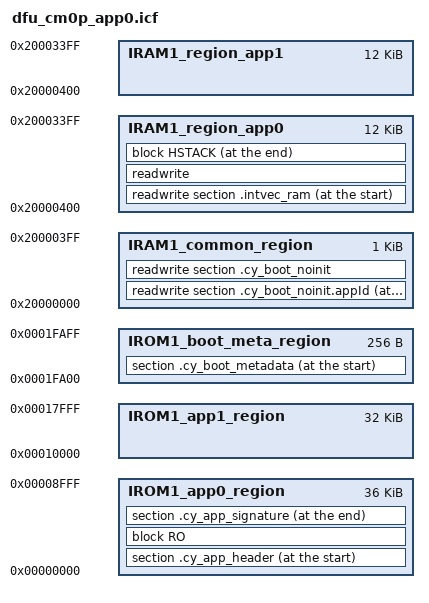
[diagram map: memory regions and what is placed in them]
/*******************************************************************************
* \file dfu_cm0p_app0.icf
* \version 4.10
*
* Linker file for the IAR compiler.
* Used for the DFU SDK application 0 firmware project.
*
* The main purpose of the linker script is to describe how the sections in the
* input files should be mapped into the output file, and to control the memory
* layout of the output file.
*
* \note The entry point is fixed and starts at 0x00000000. The valid application
* image should be placed there.
*
* \note The linker files included with the PDL template projects must be generic
* and handle all common use cases. Your project may not use every section
* defined in the linker files. In that case you may see warnings during the
* build process. In your project, you can simply comment out or remove the
* relevant code in the linker file.
*
********************************************************************************
* \copyright
* Copyright 2019-2020 Cypress Semiconductor Corporation
* SPDX-License-Identifier: Apache-2.0
*
* Licensed under the Apache License, Version 2.0 (the "License");
* you may not use this file except in compliance with the License.
* You may obtain a copy of the License at
*
*     http://www.apache.org/licenses/LICENSE-2.0
*
* Unless required by applicable law or agreed to in writing, software
* distributed under the License is distributed on an "AS IS" BASIS,
* WITHOUT WARRANTIES OR CONDITIONS OF ANY KIND, either express or implied.
* See the License for the specific language governing permissions and
* limitations under the License.
*******************************************************************************/

/*###ICF### Section handled by ICF editor, don't touch! ****/
/*-Editor annotation file-*/
/* IcfEditorFile="$TOOLKIT_DIR$\config\ide\IcfEditor\cortex_v1_4.xml" */
/*-Specials-*/
define symbol __ICFEDIT_intvec_start__ = 0x00000000;

/* The symbols below define the location and size of blocks of memory in the target.
 * Use these symbols to specify the memory regions available for allocation.
 */

/* The following symbols control RAM and flash memory allocation.
 * You can change the memory allocation by editing RAM and Flash symbols.
 */
/* RAM */
define symbol __ICFEDIT_region_IRAM1_comon_start__ = 0x20000000;
define symbol __ICFEDIT_region_IRAM1_comon_end__   = 0x200003FF;

define symbol __ICFEDIT_region_IRAM1_app0_start__ = 0x20000400;
define symbol __ICFEDIT_region_IRAM1_app0_end__   = 0x200033FF;

define symbol __ICFEDIT_region_IRAM1_app1_start__ = 0x20000400;
define symbol __ICFEDIT_region_IRAM1_app1_end__   = 0x200033FF;

/* Flash */
define symbol __ICFEDIT_region_IROM1_app0_start__ = 0x00000000;
define symbol __ICFEDIT_region_IROM1_app0_end__   = 0x00008FFF;

define symbol __ICFEDIT_region_IROM1_app1_start__ = 0x00010000;
define symbol __ICFEDIT_region_IROM1_app1_end__   = 0x00017FFF;

/* The region for DFU SDK metadata when it is outside of any application */
define symbol __ICFEDIT_region_IROM1_boot_meta_start__ = 0x0001FA00;
define symbol __ICFEDIT_region_IROM1_boot_meta_end__   = 0x0001FAFF;

/*-Sizes-*/
if (!isdefinedsymbol(__STACK_SIZE)) {
  define symbol __ICFEDIT_size_cstack__ = 0x0400;
} else {
  define symbol __ICFEDIT_size_cstack__ = __STACK_SIZE;
}
define symbol __ICFEDIT_size_proc_stack__ = 0x0;

/* Defines the minimum heap size. The actual heap size will be expanded to the end of the stack region */
if (!isdefinedsymbol(__HEAP_SIZE)) {
    define symbol __ICFEDIT_size_heap__ = 0x0080;
} else {
  define symbol __ICFEDIT_size_heap__ = __HEAP_SIZE;
}
/**** End of ICF editor section. ###ICF###*/


define memory mem with size = 4G;
define region IROM1_app0_region = mem:[from __ICFEDIT_region_IROM1_app0_start__ to __ICFEDIT_region_IROM1_app0_end__];
define region IROM1_app1_region = mem:[from __ICFEDIT_region_IROM1_app1_start__ to __ICFEDIT_region_IROM1_app1_end__];
define region IROM1_boot_meta_region  = mem:[from __ICFEDIT_region_IROM1_boot_meta_start__ to __ICFEDIT_region_IROM1_boot_meta_end__];
define region IRAM1_common_region = mem:[from __ICFEDIT_region_IRAM1_comon_start__ to __ICFEDIT_region_IRAM1_comon_end__];
define region IRAM1_region_app0   = mem:[from __ICFEDIT_region_IRAM1_app0_start__  to __ICFEDIT_region_IRAM1_app0_end__];
define region IRAM1_region_app1   = mem:[from __ICFEDIT_region_IRAM1_app1_start__  to __ICFEDIT_region_IRAM1_app1_end__];


define block CSTACK     with alignment = 8, size = __ICFEDIT_size_cstack__     { };
define block PROC_STACK with alignment = 8, size = __ICFEDIT_size_proc_stack__ { };
define block HEAP       with expanding size, alignment = 8, minimum size = __ICFEDIT_size_heap__ { };
define block HSTACK {block HEAP, block PROC_STACK, last block CSTACK};
define block RO     {first section .intvec, readonly};

/*-Initializations-*/
initialize by copy { readwrite };
do not initialize  { section .noinit, section .intvec_ram,
                     section .cy_boot_noinit.appId, section .cy_boot_noinit };

/*-Placement-*/

/* Flash */
".cy_app_header" : place at start of IROM1_app0_region  { section .cy_app_header };
place in          IROM1_app0_region  { block RO };

".cy_app_signature": place at end of IROM1_app0_region { section .cy_app_signature };

/* RAM */
place at start of IRAM1_common_region   { readwrite section .cy_boot_noinit.appId };
place in          IRAM1_common_region   { readwrite section .cy_boot_noinit };
place at start of IRAM1_region_app0  { readwrite section .intvec_ram};
place in          IRAM1_region_app0  { readwrite };
place at end   of IRAM1_region_app0  { block HSTACK };

/* These sections are used for additional metadata (silicon revision, Silicon/JTAG ID, etc.) storage. */
".cyflashprotect" : place at address mem : 0x90400000 { readonly section .cyflashprotect };
".cymeta"         : place at address mem : 0x90500000 { readonly section .cymeta };
".cychipprotect"  : place at address mem : 0x90600000 { readonly section .cychipprotect };

/* App0 uses it to initialize DFU SDK metadata, in the dfu_user.c file */
".cy_boot_metadata" : place at start of IROM1_boot_meta_region { section .cy_boot_metadata };

keep {  section .cy_app_header,
        section .cy_app_signature,
        section .cyflashprotect,
        section .cymeta,
        section .cychipprotect,
        section .cy_boot_metadata,
        section .cy_boot_noinit,
        section .cy_boot_noinit.appId,
         };


/* The following symbols used by the cymcuelftool. */
/* Flash */
define exported symbol __cy_memory_0_start    = 0x00000000;
define exported symbol __cy_memory_0_length   = 0x00020000;
define exported symbol __cy_memory_0_row_size = 0x100;

/*******************************************************************************
* The following symbols used by the cymcuelftool and dfu sdk
*******************************************************************************/

/* Used by all DFU SDK and CyMCUElfTool */
define exported symbol __cy_boot_metadata_addr   = 0x0001FA00;
define exported symbol __cy_boot_metadata_length = __cy_memory_0_row_size;

/* Used by CyMCUElfTool to generate ProductID for DFU SDK apps */
define exported symbol __cy_product_id = 0x01020304;

/* Used by CyMCUElfTool to generate ChecksumType for DFU SDK apps */
define exported symbol __cy_checksum_type = 0;

/*
* The size of the application signature.
* E.g. 4 for CRC-32,
*     32 for SHA256,
*    256 for RSA 2048.
*/
define exported symbol __cy_boot_signature_size = 4;

/* Used by DFU SDK projects, in dfu_user.c to fill in the metadata table */
define exported symbol __cy_app0_verify_start  = start(IROM1_app0_region);
define exported symbol __cy_app0_verify_length = size (IROM1_app0_region) - __cy_boot_signature_size;

define exported symbol __cy_app1_verify_start  = start(IROM1_app1_region);
define exported symbol __cy_app1_verify_length = size (IROM1_app1_region) - __cy_boot_signature_size;

/* CyMCUElfTool uses this symbol to set a proper app number */
define exported symbol __cy_app_id = 0;

/* CyMCUElfTool uses these to generate an application signature */
/* The size of the default signature (CRC-32C) is 4 bytes */
define exported symbol __cy_app_verify_start  = start(IROM1_app0_region);
define exported symbol __cy_app_verify_length =  size(IROM1_app0_region) - __cy_boot_signature_size;

/* EOF */
